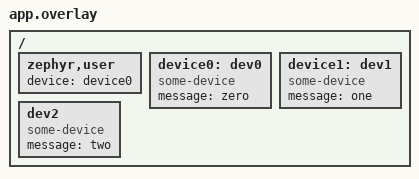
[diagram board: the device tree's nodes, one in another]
/ {
	zephyr,user {
		/* fix this next line to make
		 * the tests pass: */
		device = <&device0>;
	};

	device0: dev0 {
		compatible = "some-device";
		message = "zero";
	};

	device1: dev1 {
		compatible = "some-device";
		message = "one";
	};

	dev2 {
		compatible = "some-device";
		message = "two";
	};
};
